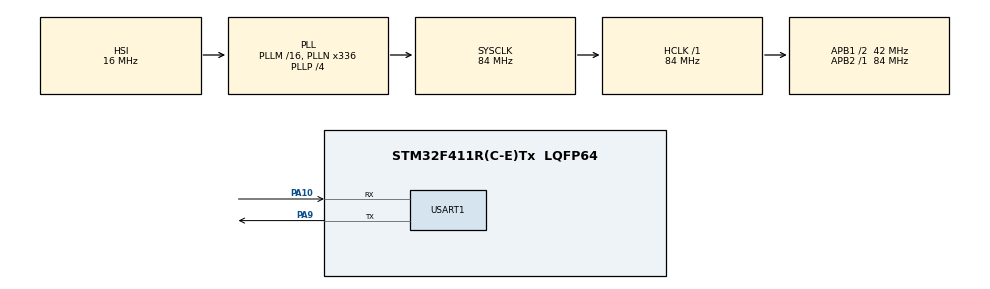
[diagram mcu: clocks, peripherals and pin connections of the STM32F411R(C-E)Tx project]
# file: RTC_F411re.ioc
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Mcu.Family=STM32F4
Mcu.Name=STM32F411R(C-E)Tx
Mcu.Package=LQFP64
NVIC.PriorityGroup=NVIC_PRIORITYGROUP_0
PA10.Mode=Asynchronous
PA10.Signal=USART1_RX
PA13.Mode=Serial_Wire
PA13.Signal=SYS_JTMS-SWDIO
PA14.Mode=Serial_Wire
PA14.Signal=SYS_JTCK-SWCLK
PA9.Mode=Asynchronous
PA9.Signal=USART1_TX
PC14-OSC32_IN.Mode=LSE-External-Oscillator
PC14-OSC32_IN.Signal=RCC_OSC32_IN
PC15-OSC32_OUT.Mode=LSE-External-Oscillator
PC15-OSC32_OUT.Signal=RCC_OSC32_OUT
PH0\ -\ OSC_IN.Mode=HSE-External-Oscillator
PH0\ -\ OSC_IN.Signal=RCC_OSC_IN
PH1\ -\ OSC_OUT.Mode=HSE-External-Oscillator
PH1\ -\ OSC_OUT.Signal=RCC_OSC_OUT
ProjectManager.HeapSize=0x200
ProjectManager.StackSize=0x400
ProjectManager.TargetToolchain=STM32CubeIDE
RCC.48MHZClocksFreq_Value=84000000
RCC.AHBFreq_Value=84000000
RCC.APB1CLKDivider=RCC_HCLK_DIV2
RCC.APB1Freq_Value=42000000
RCC.APB1TimFreq_Value=84000000
RCC.APB2Freq_Value=84000000
RCC.APB2TimFreq_Value=84000000
RCC.CortexFreq_Value=84000000
RCC.FLatency-AdvancedSettings=FLASH_LATENCY_2
RCC.HCLKFreq_Value=84000000
RCC.HSE_VALUE=8000000
RCC.HSI_VALUE=16000000
RCC.PLLN=336
RCC.PLLP=RCC_PLLP_DIV4
RCC.SYSCLKFreq_VALUE=84000000
RCC.SYSCLKSource=RCC_SYSCLKSOURCE_PLLCLK
RCC.VCOOutputFreq_Value=336000000
RTC.Date=28
RTC.Hours=9
RTC.Minutes=59
RTC.Month=RTC_MONTH_DECEMBER
RTC.WeekDay=RTC_WEEKDAY_THURSDAY
RTC.Year=23
USART1.VirtualMode=VM_ASYNC
VP_RTC_VS_RTC_Activate.Mode=RTC_Enabled
VP_RTC_VS_RTC_Calendar.Mode=RTC_Calendar
board=NUCLEO-F411RE

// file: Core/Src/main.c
/* USER CODE BEGIN Header */
/**
  ******************************************************************************
  * @file           : main.c
  * @brief          : Main program body
  ******************************************************************************
  * @attention
  *
  * Copyright (c) 2023 STMicroelectronics.
  * All rights reserved.
  *
  * This software is licensed under terms that can be found in the LICENSE file
  * in the root directory of this software component.
  * If no LICENSE file comes with this software, it is provided AS-IS.
  *
  ******************************************************************************
  */
/* USER CODE END Header */
#include "main.h"
#include<stdio.h>

/* USER CODE BEGIN PD */
int _write(int file,char *ptr,int len)
{
    int i=0;
for(i=0;i<len;i++)
    ITM_SendChar((*ptr++));
return len;
}
/* USER CODE END PD */

RTC_HandleTypeDef hrtc;

UART_HandleTypeDef huart1;

/* USER CODE BEGIN PV */
char time[30];
char date[30];

RTC_TimeTypeDef sTime;
RTC_DateTypeDef sDate;

/* USER CODE END PV */

void SystemClock_Config(void);
static void MX_GPIO_Init(void);
static void MX_RTC_Init(void);
static void MX_USART1_UART_Init(void);

int main(void)
{

  /* MCU Configuration--------------------------------------------------------*/

  /* Reset of all peripherals, Initializes the Flash interface and the Systick. */
  HAL_Init();

  /* Configure the system clock */
  SystemClock_Config();

  /* Initialize all configured peripherals */
  MX_GPIO_Init();
  MX_RTC_Init();
  MX_USART1_UART_Init();

  /* Infinite loop */
  while (1)
  {
	  HAL_RTC_GetTime(&hrtc, &sTime, RTC_FORMAT_BIN);

	  	  HAL_RTC_GetDate(&hrtc, &sDate, RTC_FORMAT_BIN);

	  	  printf("\nTime : %2d:%2d:%2d\nDate : %2d/%2d/%2d\nDay : %2d\n", sTime.Hours, sTime.Minutes, sTime.Seconds, sDate.Date, sDate.Month, sDate.Year, sDate.WeekDay);

	  	  HAL_Delay(1000);
  }
}

void SystemClock_Config(void)
{
  RCC_OscInitTypeDef RCC_OscInitStruct = {0};
  RCC_ClkInitTypeDef RCC_ClkInitStruct = {0};

  /** Configure the main internal regulator output voltage
  */
  __HAL_RCC_PWR_CLK_ENABLE();
  __HAL_PWR_VOLTAGESCALING_CONFIG(PWR_REGULATOR_VOLTAGE_SCALE1);

  /** Initializes the RCC Oscillators according to the specified parameters
  * in the RCC_OscInitTypeDef structure.
  */
  RCC_OscInitStruct.OscillatorType = RCC_OSCILLATORTYPE_HSI|RCC_OSCILLATORTYPE_LSI;
  RCC_OscInitStruct.HSIState = RCC_HSI_ON;
  RCC_OscInitStruct.HSICalibrationValue = RCC_HSICALIBRATION_DEFAULT;
  RCC_OscInitStruct.LSIState = RCC_LSI_ON;
  RCC_OscInitStruct.PLL.PLLState = RCC_PLL_ON;
  RCC_OscInitStruct.PLL.PLLSource = RCC_PLLSOURCE_HSI;
  RCC_OscInitStruct.PLL.PLLM = 16;
  RCC_OscInitStruct.PLL.PLLN = 336;
  RCC_OscInitStruct.PLL.PLLP = RCC_PLLP_DIV4;
  RCC_OscInitStruct.PLL.PLLQ = 4;
  if (HAL_RCC_OscConfig(&RCC_OscInitStruct) != HAL_OK)
  {
    Error_Handler();
  }

  /** Initializes the CPU, AHB and APB buses clocks
  */
  RCC_ClkInitStruct.ClockType = RCC_CLOCKTYPE_HCLK|RCC_CLOCKTYPE_SYSCLK
                              |RCC_CLOCKTYPE_PCLK1|RCC_CLOCKTYPE_PCLK2;
  RCC_ClkInitStruct.SYSCLKSource = RCC_SYSCLKSOURCE_PLLCLK;
  RCC_ClkInitStruct.AHBCLKDivider = RCC_SYSCLK_DIV1;
  RCC_ClkInitStruct.APB1CLKDivider = RCC_HCLK_DIV2;
  RCC_ClkInitStruct.APB2CLKDivider = RCC_HCLK_DIV1;

  if (HAL_RCC_ClockConfig(&RCC_ClkInitStruct, FLASH_LATENCY_2) != HAL_OK)
  {
    Error_Handler();
  }
}

static void MX_RTC_Init(void)
{

  RTC_TimeTypeDef sTime = {0};
  RTC_DateTypeDef sDate = {0};

  /** Initialize RTC Only
  */
  hrtc.Instance = RTC;
  hrtc.Init.HourFormat = RTC_HOURFORMAT_24;
  hrtc.Init.AsynchPrediv = 127;
  hrtc.Init.SynchPrediv = 255;
  hrtc.Init.OutPut = RTC_OUTPUT_DISABLE;
  hrtc.Init.OutPutPolarity = RTC_OUTPUT_POLARITY_HIGH;
  hrtc.Init.OutPutType = RTC_OUTPUT_TYPE_OPENDRAIN;
  if (HAL_RTC_Init(&hrtc) != HAL_OK)
  {
    Error_Handler();
  }

  /** Initialize RTC and set the Time and Date
  */
  sTime.Hours = 0x10;
  sTime.Minutes = 0x24;
  sTime.Seconds = 0x0;
  sTime.DayLightSaving = RTC_DAYLIGHTSAVING_NONE;
  sTime.StoreOperation = RTC_STOREOPERATION_RESET;
  if (HAL_RTC_SetTime(&hrtc, &sTime, RTC_FORMAT_BCD) != HAL_OK)
  {
    Error_Handler();
  }
  sDate.WeekDay = RTC_WEEKDAY_THURSDAY;
  sDate.Month = RTC_MONTH_DECEMBER;
  sDate.Date = 0x28;
  sDate.Year = 0x23;

  if (HAL_RTC_SetDate(&hrtc, &sDate, RTC_FORMAT_BCD) != HAL_OK)
  {
    Error_Handler();
  }

}

static void MX_USART1_UART_Init(void)
{

  huart1.Instance = USART1;
  huart1.Init.BaudRate = 115200;
  huart1.Init.WordLength = UART_WORDLENGTH_8B;
  huart1.Init.StopBits = UART_STOPBITS_1;
  huart1.Init.Parity = UART_PARITY_NONE;
  huart1.Init.Mode = UART_MODE_TX_RX;
  huart1.Init.HwFlowCtl = UART_HWCONTROL_NONE;
  huart1.Init.OverSampling = UART_OVERSAMPLING_16;
  if (HAL_UART_Init(&huart1) != HAL_OK)
  {
    Error_Handler();
  }

}

static void MX_GPIO_Init(void)
{

  /* GPIO Ports Clock Enable */
  __HAL_RCC_GPIOC_CLK_ENABLE();
  __HAL_RCC_GPIOH_CLK_ENABLE();
  __HAL_RCC_GPIOA_CLK_ENABLE();

}

void Error_Handler(void)
{
  __disable_irq();
  while (1)
  {
  }
}
